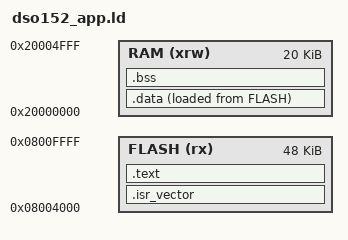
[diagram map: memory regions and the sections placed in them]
/* Linker script for FNIRSI DSO152 applications running with USB Bootloader */
ENTRY(Reset_Handler)

MEMORY
{
  FLASH (rx)      : ORIGIN = 0x08004000, LENGTH = 48K
  RAM   (xrw)     : ORIGIN = 0x20000000, LENGTH = 20K
}

_estack = ORIGIN(RAM) + LENGTH(RAM);

SECTIONS
{
  .isr_vector :
  {
    . = ALIGN(4);
    KEEP(*(.isr_vector))
    . = ALIGN(4);
  } > FLASH

  .text :
  {
    . = ALIGN(4);
    *(.text)
    *(.text*)
    *(.rodata)
    *(.rodata*)
    *(.glue_7)
    *(.glue_7t)
    . = ALIGN(4);
    _etext = .;
  } > FLASH

  _sidata = LOADADDR(.data);

  .data :
  {
    . = ALIGN(4);
    _sdata = .;
    *(.data)
    *(.data*)
    . = ALIGN(4);
    _edata = .;
  } > RAM AT > FLASH

  .bss :
  {
    . = ALIGN(4);
    _sbss = .;
    *(.bss)
    *(.bss*)
    *(COMMON)
    . = ALIGN(4);
    _ebss = .;
  } > RAM

  /DISCARD/ :
  {
    *(.ARM.attributes)
  }
}
